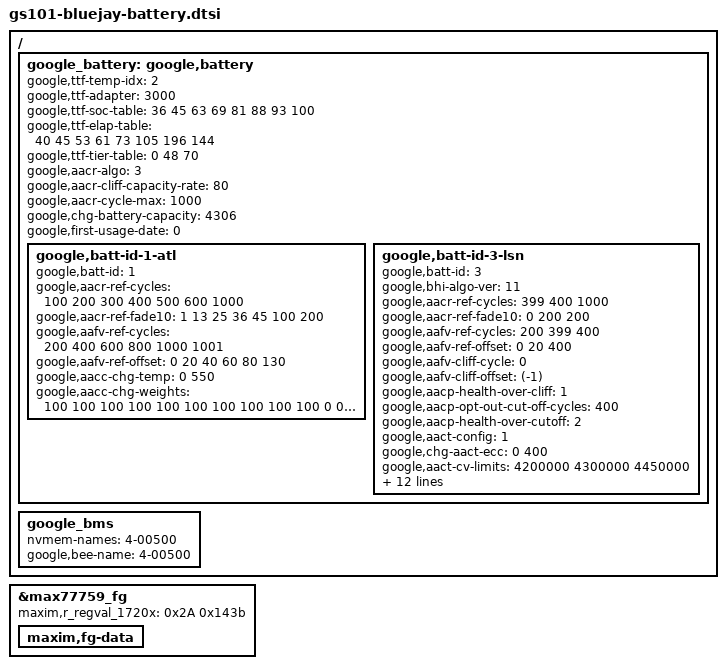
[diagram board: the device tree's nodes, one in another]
// SPDX-License-Identifier: GPL-2.0-only
/*
 * Battery device tree entries specific to bluejay
 *
 * Copyright 2021 Google,LLC
 *
 */

&google_battery {
	google,chg-battery-capacity = <4306>;
	google,first-usage-date = <0>;
};

&max77759_fg {
	maxim,r_regval_1720x = /bits/ 16 <
        0x2A 0x143b     /* RelaxCfg Register */
    >;

	maxim,fg-data {
		#include "gs101-bluejay-battery-data.dtsi"
	};
};

/ {
	fragment@battery {
		target-path = "/";
		__overlay__ {
			google_battery: google,battery {
				google,ttf-temp-idx= <2>;
				google,ttf-adapter = <3000>;
				google,ttf-soc-table =  <36 45 63 69 81 88  93  100>;
				google,ttf-elap-table = <40 45 53 61 73 105 196 144>;
				google,ttf-tier-table = <0 48 70>;

				/* 90% after 600 cycles, 80% after 1000 cycles */
				google,aacr-algo = <3>;
				google,aacr-cliff-capacity-rate = <80>;
				google,aacr-cycle-max = <1000>;

				google,batt-id-1-atl {
					google,batt-id = <1>;

					google,aacr-ref-cycles = <100 200 300 400 500 600 1000>;
					google,aacr-ref-fade10 = <  1  13  25  36  45 100  200>;
					google,aafv-ref-cycles = <200 400 600 800 1000 1001>;
					google,aafv-ref-offset = <  0  20  40  60   80  130>;
					google,aacc-chg-temp = <0 550>;
					google,aacc-chg-weights = < /* units: 1/1000 cycles */
						100 100 100 100 100 100 100 100 100 100
						  0   0   0   0   0   0   0   0   0   0
						  0   0   0   0   0   0   0   0   0   0
						  0   0   0   0   0   0   0   0   0   0
						  0   0   0   0   0   0   0   0   0   0
						  0   0   0   0   0   0   0   0   0   0
						  0   0   0   0   0   0   0   0   0   0
						  0   0   0   0   0   0   0   0   0   0
						  0   0   0   0   0   0   0   0   0   0
						  0   0   0   0   0   0   0   0   0   0
					>;
				};

				google,batt-id-3-lsn {
					google,batt-id = <3>;
					google,bhi-algo-ver = <11>;

					google,aacr-ref-cycles = <399 400 1000>;
					google,aacr-ref-fade10 = <  0 200  200>;
					google,aafv-ref-cycles = <200 399 400>;
					google,aafv-ref-offset = <  0  20 400>;

					google,aafv-cliff-cycle = <0>;
					google,aafv-cliff-offset = <(-1)>;
					google,aacp-health-over-cliff = <1>;
					google,aacp-opt-out-cut-off-cycles = <400>;
					google,aacp-health-over-cutoff = <2>;

					google,aact-config = <1>;
					google,chg-aact-ecc = <0 400>;
					google,aact-cv-limits = <4200000 4300000 4450000>;
					google,aact-temp-limits = <0 100 200 420 460 480 550>;
					google,aact-cc-limits = <
						 30  10   0
						 50  30  30
						100  70  50
						 80  50  50
						 50  50   0
						 30   0   0
					>;

					/* support aact multiple-profiles */
					google,aact-support-multiple-profiles;
					google,aact-cv-limits-1 = <4450000>;
					google,aact-temp-limits-1 = <0 100 200 420 460 480 550>;
					google,aact-cc-limits-1 = <30 50 100 80 50 30>;
					google,aacc-chg-temp = <0 550>;
					google,aacc-chg-weights = < /* units: 1/1000 cycles */
						100 100 100 100 100 100 100 100 100 100
						  0   0   0   0   0   0   0   0   0   0
						  0   0   0   0   0   0   0   0   0   0
						  0   0   0   0   0   0   0   0   0   0
						  0   0   0   0   0   0   0   0   0   0
						  0   0   0   0   0   0   0   0   0   0
						  0   0   0   0   0   0   0   0   0   0
						  0   0   0   0   0   0   0   0   0   0
						  0   0   0   0   0   0   0   0   0   0
						  0   0   0   0   0   0   0   0   0   0
					>;
				};
			};
			google_bms {
				nvmem-names = "4-00500";
				/* pack eeprom is available only with P20+ batteries */
				google,bee-name = "4-00500";
			};
		};
	};
};
